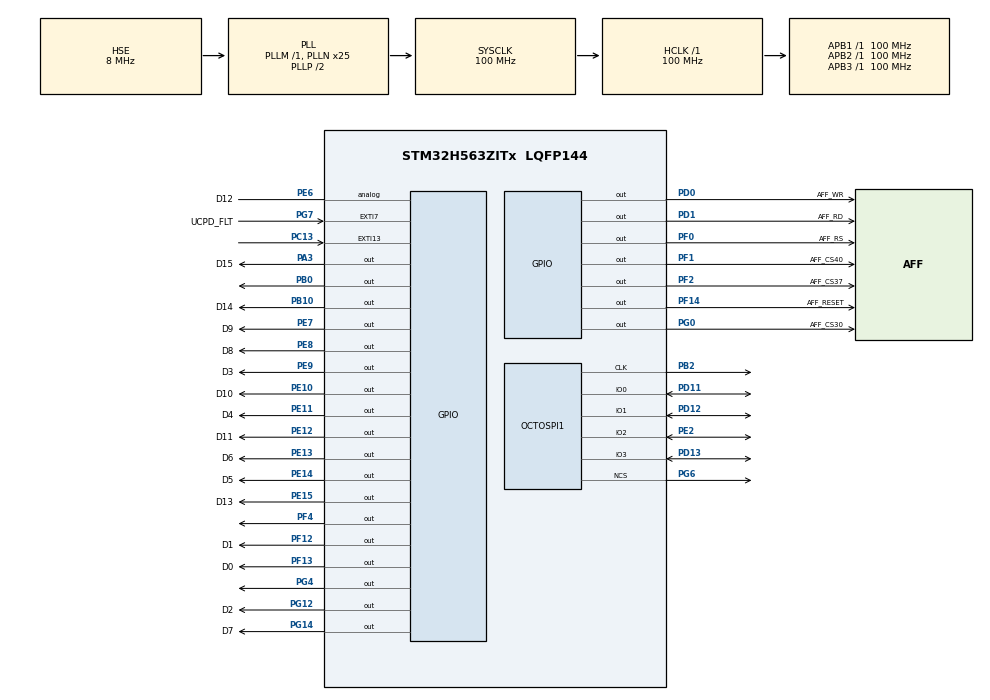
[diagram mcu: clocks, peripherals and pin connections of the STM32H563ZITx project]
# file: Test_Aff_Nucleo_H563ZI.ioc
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BOOTPATH.BootPathName=LEGACY
BOOTPATH.UserSelectedBootPath=LEGACY
CORTEX_M33_NS.userName=CORTEX_M33
Mcu.Family=STM32H5
Mcu.Name=STM32H563ZITx
Mcu.Package=LQFP144
NUCLEO-H563ZI.BUTTON=1
NUCLEO-H563ZI.Bsp_Common_DEMO=true
NUCLEO-H563ZI.LD1=true
NUCLEO-H563ZI.LD2=true
NUCLEO-H563ZI.LD3=true
NVIC.EXTI13_IRQn=true\:0\:0\:false\:false\:true\:false\:true\:true
NVIC.PriorityGroup=NVIC_PRIORITYGROUP_4
OCTOSPI1.DeviceType=SPI_DEVICE_FLASH
OCTOSPI1.MemorySize=HAL_XSPI_SIZE_32MB
OCTOSPI1.MemoryType=HAL_XSPI_MEMTYPE_MACRONIX
PA1.GPIO_Label=RMII_REF_CLK
PA1.GPIO_Mode=GPIO_MODE_AF_PP
PA1.GPIO_PuPd=GPIO_NOPULL
PA1.GPIO_Speed=GPIO_SPEED_FREQ_LOW
PA1.Signal=ETH_REF_CLK
PA11.GPIO_Label=USB_FS_N
PA11.Signal=USB_DM
PA12.GPIO_Label=USB_FS_P
PA12.Signal=USB_DP
PA13(JTMS/SWDIO).GPIO_Label=SWDIO
PA13(JTMS/SWDIO).Signal=DEBUG_JTMS-SWDIO
PA14(JTCK/SWCLK).GPIO_Label=SWCLK
PA14(JTCK/SWCLK).Signal=DEBUG_JTCK-SWCLK
PA15(JTDI).GPIO_Label=T_JTDI
PA15(JTDI).Signal=DEBUG_JTDI
PA2.GPIO_Label=RMII_MDIO
PA2.GPIO_Mode=GPIO_MODE_AF_PP
PA2.GPIO_PuPd=GPIO_NOPULL
PA2.GPIO_Speed=GPIO_SPEED_FREQ_LOW
PA2.Signal=ETH_MDIO
PA3.GPIO_Label=D15
PA3.Signal=GPIO_Output
PA4.GPIO_Label=VBUS_SENSE
PA4.Signal=ADCx_INP18
PA7.GPIO_Label=RMII_CRS_DV
PA7.GPIO_Mode=GPIO_MODE_AF_PP
PA7.GPIO_PuPd=GPIO_NOPULL
PA7.GPIO_Speed=GPIO_SPEED_FREQ_LOW
PA7.Signal=ETH_CRS_DV
PA9.GPIO_Label=UCDP_DBn
PA9.Signal=UCPD1_DB1
PB0.Signal=GPIO_Output
PB10.GPIO_Label=D14
PB10.Signal=GPIO_Output
PB13.GPIO_Label=UCPD_CC1
PB13.Signal=UCPD1_CC1
PB14.GPIO_Label=UCPD_CC2
PB14.Signal=UCPD1_CC2
PB15.GPIO_Label=RMII_TXD1
PB15.GPIO_Mode=GPIO_MODE_AF_PP
PB15.GPIO_PuPd=GPIO_NOPULL
PB15.GPIO_Speed=GPIO_SPEED_FREQ_LOW
PB15.Signal=ETH_TXD1
PB2.Mode=quad_mode
PB2.Signal=OCTOSPI1_CLK
PB3(JTDO/TRACESWO).GPIO_Label=SWO
PB3(JTDO/TRACESWO).Signal=DEBUG_JTDO-SWO
PB5.Signal=SPI1_MOSI
PB6.GPIO_Label=ARD_D1_TX
PB6.Signal=LPUART1_TX
PB7.GPIO_Label=ARD_D0_RX
PB7.Signal=LPUART1_RX
PC1.GPIO_Label=RMII_MDC
PC1.GPIO_Mode=GPIO_MODE_AF_PP
PC1.GPIO_PuPd=GPIO_NOPULL
PC1.GPIO_Speed=GPIO_SPEED_FREQ_LOW
PC1.Signal=ETH_MDC
PC13.Signal=GPXTI13
PC14-OSC32_IN(OSC32_IN).Mode=LSE-External-Oscillator
PC14-OSC32_IN(OSC32_IN).Signal=RCC_OSC32_IN
PC15-OSC32_OUT(OSC32_OUT).Mode=LSE-External-Oscillator
PC15-OSC32_OUT(OSC32_OUT).Signal=RCC_OSC32_OUT
PC4.GPIO_Label=RMII_RXD0
PC4.GPIO_Mode=GPIO_MODE_AF_PP
PC4.GPIO_PuPd=GPIO_NOPULL
PC4.GPIO_Speed=GPIO_SPEED_FREQ_LOW
PC4.Signal=ETH_RXD0
PC5.GPIO_Label=RMII_RXD1
PC5.GPIO_Mode=GPIO_MODE_AF_PP
PC5.GPIO_PuPd=GPIO_NOPULL
PC5.GPIO_Speed=GPIO_SPEED_FREQ_LOW
PC5.Signal=ETH_RXD1
PD0.GPIO_Label=AFF_WR
PD0.Signal=GPIO_Output
PD1.GPIO_Label=AFF_RD
PD1.Signal=GPIO_Output
PD11.Mode=OCTOSPI1_IO[3\:0]
PD11.Signal=OCTOSPI1_IO0
PD12.Mode=OCTOSPI1_IO[3\:0]
PD12.Signal=OCTOSPI1_IO1
PD13.Mode=OCTOSPI1_IO[3\:0]
PD13.Signal=OCTOSPI1_IO3
PD8.Signal=USART3_TX
PD9.Signal=USART3_RX
PE10.GPIO_Label=D10
PE10.Signal=GPIO_Output
PE11.GPIO_Label=D4
PE11.Signal=GPIO_Output
PE12.GPIO_Label=D11
PE12.Signal=GPIO_Output
PE13.GPIO_Label=D6
PE13.Signal=GPIO_Output
PE14.GPIO_Label=D5
PE14.Signal=GPIO_Output
PE15.GPIO_Label=D13
PE15.Signal=GPIO_Output
PE2.Mode=OCTOSPI1_IO[3\:0]
PE2.Signal=OCTOSPI1_IO2
PE3.GPIO_Label=TRACE_D0
PE3.Signal=DEBUG_TRACED0
PE4.GPIO_Label=TRACE_D1
PE4.Signal=DEBUG_TRACED1
PE5.GPIO_Label=TRACE_D2
PE5.Signal=DEBUG_TRACED2
PE6.GPIO_Label=D12
PE6.Signal=GPIO_Analog
PE7.GPIO_Label=D9
PE7.Signal=GPIO_Output
PE8.GPIO_Label=D8
PE8.Signal=GPIO_Output
PE9.GPIO_Label=D3
PE9.Signal=GPIO_Output
PF0.GPIO_Label=AFF_RS
PF0.Signal=GPIO_Output
PF1.GPIO_Label=AFF_CS40
PF1.Signal=GPIO_Output
PF12.GPIO_Label=D1
PF12.Signal=GPIO_Output
PF13.GPIO_Label=D0
PF13.Signal=GPIO_Output
PF14.GPIO_Label=AFF_RESET
PF14.Signal=GPIO_Output
PF2.GPIO_Label=AFF_CS37
PF2.Signal=GPIO_Output
PF4.Signal=GPIO_Output
PG0.GPIO_Label=AFF_CS30
PG0.Signal=GPIO_Output
PG11.GPIO_Label=RMII_TXT_EN
PG11.GPIO_Mode=GPIO_MODE_AF_PP
PG11.GPIO_PuPd=GPIO_NOPULL
PG11.GPIO_Speed=GPIO_SPEED_FREQ_LOW
PG11.Signal=ETH_TX_EN
PG12.GPIO_Label=D2
PG12.Signal=GPIO_Output
PG13.GPIO_Label=RMI_TXD0
PG13.GPIO_Mode=GPIO_MODE_AF_PP
PG13.GPIO_PuPd=GPIO_NOPULL
PG13.GPIO_Speed=GPIO_SPEED_FREQ_LOW
PG13.Signal=ETH_TXD0
PG14.GPIO_Label=D7
PG14.Signal=GPIO_Output
PG4.Signal=GPIO_Output
PG6.Mode=quad_mode
PG6.Signal=OCTOSPI1_NCS
PG7.GPIO_Label=UCPD_FLT
PG7.Signal=GPXTI7
PG9.Signal=SPI1_MISO
PH0-OSC_IN(PH0).GPIO_Label=STLK_MCO
PH0-OSC_IN(PH0).Mode=HSE-External-Clock-Source
PH0-OSC_IN(PH0).Signal=RCC_OSC_IN
ProjectManager.HeapSize=0x1000
ProjectManager.StackSize=0x1000
ProjectManager.TargetToolchain=STM32CubeIDE
RCC.ADCFreq_Value=100000000
RCC.AHBFreq_Value=100000000
RCC.APB1Freq_Value=100000000
RCC.APB1TimFreq_Value=100000000
RCC.APB2Freq_Value=100000000
RCC.APB2TimFreq_Value=100000000
RCC.APB3Freq_Value=100000000
RCC.CSI_VALUE=4000000
RCC.CortexFreq_Value=100000000
RCC.EPOD_VALUE=8000000
RCC.HCLKFreq_Value=100000000
RCC.HSE_VALUE=8000000
RCC.HSI48_VALUE=48000000
RCC.HSIDiv=RCC_HSI_DIV1
RCC.HSI_VALUE=64000000
RCC.LSIRC_VALUE=32000
RCC.PLLFRACN=0
RCC.PLLN=25
RCC.PLLSourceVirtual=RCC_PLL1_SOURCE_HSE
RCC.SYSCLKFreq_VALUE=100000000
RCC.SYSCLKSource=RCC_SYSCLKSOURCE_PLLCLK
RCC.USBFreq_Value=48000000
RCC.VCOOutputFreq_Value=200000000
SH.ADCx_INP18.0=ADC1_INP18
VP_BOOTPATH_VS_BOOTPATH.Mode=BP_Activate
VP_CORTEX_M33_NS_VS_Hclk.Mode=Hclk_Mode
VP_CRC_VS_CRC.Mode=CRC_Activate
VP_MEMORYMAP_VS_MEMORYMAP.Mode=CurAppReg
VP_NUCLEO-H563ZI_VS_BSP_COMMON.Mode=COMMON
VP_PWR_VS_DBSignals.Mode=DisableDeadBatterySignals
VP_PWR_VS_LPOM.Mode=PowerOptimisation
VP_PWR_VS_SECSignals.Mode=Security/Privilege
board=NUCLEO-H563ZI

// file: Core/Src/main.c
/* USER CODE BEGIN Header */
/**
  ******************************************************************************
  * @file           : main.c
  * @brief          : Main program body
  ******************************************************************************
  * @attention
  *
  * Copyright (c) 2024 STMicroelectronics.
  * All rights reserved.
  *
  * This software is licensed under terms that can be found in the LICENSE file
  * in the root directory of this software component.
  * If no LICENSE file comes with this software, it is provided AS-IS.
  *
  ******************************************************************************
  */
/* USER CODE END Header */
#include "main.h"
#include "crc.h"
#include "memorymap.h"
#include "octospi.h"
#include "gpio.h"

/* USER CODE BEGIN Includes */
#include "BaseDeTemps.h"
#include "GestionLedAlive.h"
/* USER CODE END Includes */

__IO uint32_t BspButtonState = BUTTON_RELEASED;

void SystemClock_Config(void);

int main(void)
{

  /* MCU Configuration--------------------------------------------------------*/

  /* Reset of all peripherals, Initializes the Flash interface and the Systick. */
  HAL_Init();

  /* Configure the system clock */
  SystemClock_Config();

  /* Initialize all configured peripherals */
  MX_GPIO_Init();
  MX_OCTOSPI1_Init();
  MX_CRC_Init();
  /* USER CODE BEGIN 2 */
  InitBaseDeTemps();
  InitGestionLed();
  /* USER CODE END 2 */

  /* Initialize leds */
  BSP_LED_Init(LED_GREEN);
  BSP_LED_Init(LED_YELLOW);
  BSP_LED_Init(LED_RED);

  /* Initialize USER push-button, will be used to trigger an interrupt each time it's pressed.*/
  BSP_PB_Init(BUTTON_USER, BUTTON_MODE_EXTI);

  /* USER CODE BEGIN BSP */
  /* -- Sample board code to switch on leds ---- */;
  BSP_LED_On(LED_RED);
  SetBlinkMode(E_LED_CLIGN_RAPIDE_2);
  /* USER CODE END BSP */

  /* Infinite loop */
  /* USER CODE BEGIN WHILE */
  while (1)
  {
	  GestionBaseDeTemps();
    /* -- Sample board code for User push-button in interrupt mode ---- */
    if (BspButtonState == BUTTON_PRESSED)
    {
      /* Update button state */
      BspButtonState = BUTTON_RELEASED;
      /* -- Sample board code to toggle leds ---- */
      BSP_LED_Toggle(LED_YELLOW);
      /* ..... Perform your action ..... */
    }
    /* USER CODE END WHILE */

  }
}

void SystemClock_Config(void)
{
  RCC_OscInitTypeDef RCC_OscInitStruct = {0};
  RCC_ClkInitTypeDef RCC_ClkInitStruct = {0};

  /** Configure the main internal regulator output voltage
  */
  __HAL_PWR_VOLTAGESCALING_CONFIG(PWR_REGULATOR_VOLTAGE_SCALE3);

  while(!__HAL_PWR_GET_FLAG(PWR_FLAG_VOSRDY)) {}

  /** Initializes the RCC Oscillators according to the specified parameters
  * in the RCC_OscInitTypeDef structure.
  */
  RCC_OscInitStruct.OscillatorType = RCC_OSCILLATORTYPE_HSE;
  RCC_OscInitStruct.HSEState = RCC_HSE_BYPASS;
  RCC_OscInitStruct.PLL.PLLState = RCC_PLL_ON;
  RCC_OscInitStruct.PLL.PLLSource = RCC_PLL1_SOURCE_HSE;
  RCC_OscInitStruct.PLL.PLLM = 1;
  RCC_OscInitStruct.PLL.PLLN = 25;
  RCC_OscInitStruct.PLL.PLLP = 2;
  RCC_OscInitStruct.PLL.PLLQ = 2;
  RCC_OscInitStruct.PLL.PLLR = 2;
  RCC_OscInitStruct.PLL.PLLRGE = RCC_PLL1_VCIRANGE_3;
  RCC_OscInitStruct.PLL.PLLVCOSEL = RCC_PLL1_VCORANGE_WIDE;
  RCC_OscInitStruct.PLL.PLLFRACN = 0;
  if (HAL_RCC_OscConfig(&RCC_OscInitStruct) != HAL_OK)
  {
    Error_Handler();
  }

  /** Initializes the CPU, AHB and APB buses clocks
  */
  RCC_ClkInitStruct.ClockType = RCC_CLOCKTYPE_HCLK|RCC_CLOCKTYPE_SYSCLK
                              |RCC_CLOCKTYPE_PCLK1|RCC_CLOCKTYPE_PCLK2
                              |RCC_CLOCKTYPE_PCLK3;
  RCC_ClkInitStruct.SYSCLKSource = RCC_SYSCLKSOURCE_PLLCLK;
  RCC_ClkInitStruct.AHBCLKDivider = RCC_SYSCLK_DIV1;
  RCC_ClkInitStruct.APB1CLKDivider = RCC_HCLK_DIV1;
  RCC_ClkInitStruct.APB2CLKDivider = RCC_HCLK_DIV1;
  RCC_ClkInitStruct.APB3CLKDivider = RCC_HCLK_DIV1;

  if (HAL_RCC_ClockConfig(&RCC_ClkInitStruct, FLASH_LATENCY_4) != HAL_OK)
  {
    Error_Handler();
  }

  /** Configure the programming delay
  */
  __HAL_FLASH_SET_PROGRAM_DELAY(FLASH_PROGRAMMING_DELAY_2);
}

/**
  * @brief  BSP Push Button callback
  * @param  Button Specifies the pressed button
  * @retval None
  */
void BSP_PB_Callback(Button_TypeDef Button)
{
  if (Button == BUTTON_USER)
  {
    BspButtonState = BUTTON_PRESSED;
  }
}

void Error_Handler(void)
{
  __disable_irq();
  while (1)
  {
  }
}
